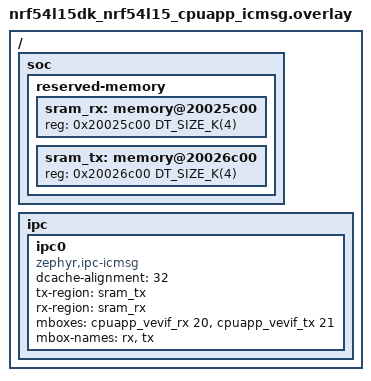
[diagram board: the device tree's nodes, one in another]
/*
 * Copyright (c) 2026 Nordic Semiconductor ASA
 *
 * SPDX-License-Identifier: Apache-2.0
 */

#include "nrf54l15dk_nrf54l15_cpuapp_common.dtsi"

/ {
	soc {
		reserved-memory {
			#address-cells = <1>;
			#size-cells = <1>;

			sram_rx: memory@20025c00 {
				reg = <0x20025c00 DT_SIZE_K(4)>;
			};

			sram_tx: memory@20026c00 {
				reg = <0x20026c00 DT_SIZE_K(4)>;
			};
		};
	};

	ipc {
		ipc0: ipc0 {
			compatible = "zephyr,ipc-icmsg";
			dcache-alignment = <32>;
			tx-region = <&sram_tx>;
			rx-region = <&sram_rx>;
			mboxes = <&cpuapp_vevif_rx 20>, <&cpuapp_vevif_tx 21>;
			mbox-names = "rx", "tx";
			status = "okay";
		};
	};
};
